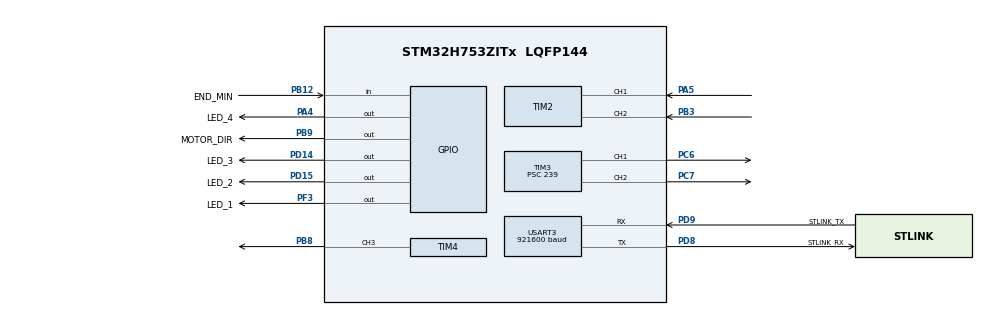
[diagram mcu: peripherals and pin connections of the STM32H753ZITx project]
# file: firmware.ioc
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CORTEX_M7.CPU_DCache=Disabled
CORTEX_M7.CPU_ICache=Disabled
CORTEX_M7.MPU_Control=MPU_PRIVILEGED_DEFAULT
CORTEX_M7.default_mode_Activation=1
Mcu.Family=STM32H7
Mcu.Name=STM32H753ZITx
Mcu.Package=LQFP144
NVIC.PriorityGroup=NVIC_PRIORITYGROUP_4
NVIC.USART3_IRQn=true\:0\:0\:false\:false\:true\:true\:true\:true
PA5.Signal=S_TIM2_CH1_ETR
PB3\ (JTDO/TRACESWO).Signal=S_TIM2_CH2
PC14-OSC32_IN\ (OSC32_IN).Signal=RCC_OSC32_IN
PC15-OSC32_OUT\ (OSC32_OUT).Signal=RCC_OSC32_OUT
PC6.Signal=S_TIM3_CH1
PC7.Signal=S_TIM3_CH2
PD14.GPIO_Label=LED_3
PD14.Signal=GPIO_Output
PD15.GPIO_Label=LED_2
PD15.Signal=GPIO_Output
PD8.GPIO_Label=STLINK_RX
PD8.Mode=Asynchronous
PD8.Signal=USART3_TX
PD9.GPIO_Label=STLINK_TX
PD9.Mode=Asynchronous
PD9.Signal=USART3_RX
PA4.GPIO_Label=LED_4
PA4.Signal=GPIO_Output
PB8.Signal=S_TIM4_CH3
PF3.GPIO_Label=LED_1
PF3.Signal=GPIO_Output
PB9.GPIO_Label=MOTOR_DIR
PB9.Signal=GPIO_Output
PB12.GPIO_Label=END_MIN
PB12.Signal=GPIO_Input
PH0-OSC_IN\ (PH0).Signal=RCC_OSC_IN
PH1-OSC_OUT\ (PH1).Signal=RCC_OSC_OUT
ProjectManager.HeapSize=0x200
ProjectManager.StackSize=0x400
ProjectManager.TargetToolchain=CMake
RCC.ADCFreq_Value=129000000
RCC.APB1Freq_Value=120000000
RCC.APB2Freq_Value=120000000
RCC.APB3Freq_Value=120000000
RCC.APB4Freq_Value=120000000
RCC.CortexFreq_Value=480000000
RCC.D1PPRE=RCC_APB3_DIV2
RCC.D2PPRE1=RCC_APB1_DIV2
RCC.D2PPRE2=RCC_APB2_DIV2
RCC.D3PPRE=RCC_APB4_DIV2
RCC.DIVM1=4
RCC.DIVN1=60
RCC.DIVQ1=4
RCC.HCLKFreq_Value=240000000
RCC.HPRE=RCC_HCLK_DIV2
RCC.HSE_VALUE=8000000
RCC.PLL2FRACN=0
RCC.PLL3FRACN=0
RCC.PLLFRACN=0
RCC.PWR_Regulator_Voltage_Scale=PWR_REGULATOR_VOLTAGE_SCALE0
RCC.SYSCLKFreq_VALUE=480000000
RCC.SYSCLKSource=RCC_SYSCLKSOURCE_PLLCLK
RCC.USBFreq_Value=240000000
SH.S_TIM2_CH1_ETR.0=TIM2_CH1,Encoder_Interface
SH.S_TIM2_CH2.0=TIM2_CH2,Encoder_Interface
SH.S_TIM3_CH1.0=TIM3_CH1,PWM Generation1 CH1
SH.S_TIM3_CH2.0=TIM3_CH2,PWM Generation2 CH2
SH.S_TIM4_CH3.0=TIM4_CH3,PWM Generation3 CH3
TIM2.EncoderMode=TIM_ENCODERMODE_TI12
TIM2.IC1Filter=6
TIM2.IC2Filter=6
TIM3.Channel-PWM\ Generation1\ CH1=TIM_CHANNEL_1
TIM3.Channel-PWM\ Generation2\ CH2=TIM_CHANNEL_2
TIM3.Period=19999
TIM3.Prescaler=239
TIM4.Channel-PWM\ Generation3\ CH3=TIM_CHANNEL_3
TIM4.Period=11999
USART3.BaudRate=921600
USART3.VirtualMode-Asynchronous=VM_ASYNC
VP_MEMORYMAP_VS_MEMORYMAP.Mode=CurAppReg
board=NUCLEO-H753ZI

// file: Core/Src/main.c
/* USER CODE BEGIN Header */
/**
  ******************************************************************************
  * @file           : main.c
  * @brief          : Main program body
  ******************************************************************************
  * @attention
  *
  * Copyright (c) 2026 STMicroelectronics.
  * All rights reserved.
  *
  * This software is licensed under terms that can be found in the LICENSE file
  * in the root directory of this software component.
  * If no LICENSE file comes with this software, it is provided AS-IS.
  *
  ******************************************************************************
  */
/* USER CODE END Header */
#include "main.h"

/* USER CODE BEGIN Includes */
#include "app.h"
#include "bsp/bsp_stm32h7.h"
/* USER CODE END Includes */

TIM_HandleTypeDef htim2;
TIM_HandleTypeDef htim3;
TIM_HandleTypeDef htim4;

UART_HandleTypeDef huart3;

void SystemClock_Config(void);
static void MPU_Config(void);
static void MX_GPIO_Init(void);
static void MX_TIM2_Init(void);
static void MX_TIM3_Init(void);
static void MX_TIM4_Init(void);
static void MX_USART3_UART_Init(void);

int main(void)
{

  /* MPU Configuration--------------------------------------------------------*/
  MPU_Config();

  /* MCU Configuration--------------------------------------------------------*/

  /* Reset of all peripherals, Initializes the Flash interface and the Systick. */
  HAL_Init();

  /* Configure the system clock */
  SystemClock_Config();

  /* Initialize all configured peripherals */
  MX_GPIO_Init();
  MX_TIM2_Init();
  MX_TIM3_Init();
  MX_TIM4_Init();
  MX_USART3_UART_Init();
  /* USER CODE BEGIN 2 */
  bsp_start();
  app_init();
  /* USER CODE END 2 */

  /* Infinite loop */
  while (1)
  {

    /* USER CODE BEGIN 3 */
    app_poll();
  }
  /* USER CODE END 3 */
}

void SystemClock_Config(void)
{
  RCC_OscInitTypeDef RCC_OscInitStruct = {0};
  RCC_ClkInitTypeDef RCC_ClkInitStruct = {0};

  /** Supply configuration update enable
  */
  HAL_PWREx_ConfigSupply(PWR_LDO_SUPPLY);

  /** Configure the main internal regulator output voltage
  */
  __HAL_PWR_VOLTAGESCALING_CONFIG(PWR_REGULATOR_VOLTAGE_SCALE0);

  while(!__HAL_PWR_GET_FLAG(PWR_FLAG_VOSRDY)) {}

  /** Initializes the RCC Oscillators according to the specified parameters
  * in the RCC_OscInitTypeDef structure.
  */
  RCC_OscInitStruct.OscillatorType = RCC_OSCILLATORTYPE_HSI;
  RCC_OscInitStruct.HSIState = RCC_HSI_DIV1;
  RCC_OscInitStruct.HSICalibrationValue = RCC_HSICALIBRATION_DEFAULT;
  RCC_OscInitStruct.PLL.PLLState = RCC_PLL_ON;
  RCC_OscInitStruct.PLL.PLLSource = RCC_PLLSOURCE_HSI;
  RCC_OscInitStruct.PLL.PLLM = 4;
  RCC_OscInitStruct.PLL.PLLN = 60;
  RCC_OscInitStruct.PLL.PLLP = 2;
  RCC_OscInitStruct.PLL.PLLQ = 4;
  RCC_OscInitStruct.PLL.PLLR = 2;
  RCC_OscInitStruct.PLL.PLLRGE = RCC_PLL1VCIRANGE_3;
  RCC_OscInitStruct.PLL.PLLVCOSEL = RCC_PLL1VCOWIDE;
  RCC_OscInitStruct.PLL.PLLFRACN = 0;
  if (HAL_RCC_OscConfig(&RCC_OscInitStruct) != HAL_OK)
  {
    Error_Handler();
  }

  /** Initializes the CPU, AHB and APB buses clocks
  */
  RCC_ClkInitStruct.ClockType = RCC_CLOCKTYPE_HCLK|RCC_CLOCKTYPE_SYSCLK
                              |RCC_CLOCKTYPE_PCLK1|RCC_CLOCKTYPE_PCLK2
                              |RCC_CLOCKTYPE_D3PCLK1|RCC_CLOCKTYPE_D1PCLK1;
  RCC_ClkInitStruct.SYSCLKSource = RCC_SYSCLKSOURCE_PLLCLK;
  RCC_ClkInitStruct.SYSCLKDivider = RCC_SYSCLK_DIV1;
  RCC_ClkInitStruct.AHBCLKDivider = RCC_HCLK_DIV2;
  RCC_ClkInitStruct.APB3CLKDivider = RCC_APB3_DIV2;
  RCC_ClkInitStruct.APB1CLKDivider = RCC_APB1_DIV2;
  RCC_ClkInitStruct.APB2CLKDivider = RCC_APB2_DIV2;
  RCC_ClkInitStruct.APB4CLKDivider = RCC_APB4_DIV2;

  if (HAL_RCC_ClockConfig(&RCC_ClkInitStruct, FLASH_LATENCY_4) != HAL_OK)
  {
    Error_Handler();
  }
}

static void MX_TIM2_Init(void)
{

  TIM_Encoder_InitTypeDef sConfig = {0};
  TIM_MasterConfigTypeDef sMasterConfig = {0};

  htim2.Instance = TIM2;
  htim2.Init.Prescaler = 0;
  htim2.Init.CounterMode = TIM_COUNTERMODE_UP;
  htim2.Init.Period = 4294967295;
  htim2.Init.ClockDivision = TIM_CLOCKDIVISION_DIV1;
  htim2.Init.AutoReloadPreload = TIM_AUTORELOAD_PRELOAD_DISABLE;
  sConfig.EncoderMode = TIM_ENCODERMODE_TI12;
  sConfig.IC1Polarity = TIM_ICPOLARITY_RISING;
  sConfig.IC1Selection = TIM_ICSELECTION_DIRECTTI;
  sConfig.IC1Prescaler = TIM_ICPSC_DIV1;
  sConfig.IC1Filter = 6;
  sConfig.IC2Polarity = TIM_ICPOLARITY_RISING;
  sConfig.IC2Selection = TIM_ICSELECTION_DIRECTTI;
  sConfig.IC2Prescaler = TIM_ICPSC_DIV1;
  sConfig.IC2Filter = 6;
  if (HAL_TIM_Encoder_Init(&htim2, &sConfig) != HAL_OK)
  {
    Error_Handler();
  }
  sMasterConfig.MasterOutputTrigger = TIM_TRGO_RESET;
  sMasterConfig.MasterSlaveMode = TIM_MASTERSLAVEMODE_DISABLE;
  if (HAL_TIMEx_MasterConfigSynchronization(&htim2, &sMasterConfig) != HAL_OK)
  {
    Error_Handler();
  }

}

static void MX_TIM3_Init(void)
{

  TIM_MasterConfigTypeDef sMasterConfig = {0};
  TIM_OC_InitTypeDef sConfigOC = {0};

  htim3.Instance = TIM3;
  htim3.Init.Prescaler = 239;
  htim3.Init.CounterMode = TIM_COUNTERMODE_UP;
  htim3.Init.Period = 19999;
  htim3.Init.ClockDivision = TIM_CLOCKDIVISION_DIV1;
  htim3.Init.AutoReloadPreload = TIM_AUTORELOAD_PRELOAD_DISABLE;
  if (HAL_TIM_PWM_Init(&htim3) != HAL_OK)
  {
    Error_Handler();
  }
  sMasterConfig.MasterOutputTrigger = TIM_TRGO_RESET;
  sMasterConfig.MasterSlaveMode = TIM_MASTERSLAVEMODE_DISABLE;
  if (HAL_TIMEx_MasterConfigSynchronization(&htim3, &sMasterConfig) != HAL_OK)
  {
    Error_Handler();
  }
  sConfigOC.OCMode = TIM_OCMODE_PWM1;
  sConfigOC.Pulse = 0;
  sConfigOC.OCPolarity = TIM_OCPOLARITY_HIGH;
  sConfigOC.OCFastMode = TIM_OCFAST_DISABLE;
  if (HAL_TIM_PWM_ConfigChannel(&htim3, &sConfigOC, TIM_CHANNEL_1) != HAL_OK)
  {
    Error_Handler();
  }
  if (HAL_TIM_PWM_ConfigChannel(&htim3, &sConfigOC, TIM_CHANNEL_2) != HAL_OK)
  {
    Error_Handler();
  }
  HAL_TIM_MspPostInit(&htim3);

}

static void MX_TIM4_Init(void)
{

  TIM_MasterConfigTypeDef sMasterConfig = {0};
  TIM_OC_InitTypeDef sConfigOC = {0};

  htim4.Instance = TIM4;
  htim4.Init.Prescaler = 0;
  htim4.Init.CounterMode = TIM_COUNTERMODE_UP;
  htim4.Init.Period = 11999;
  htim4.Init.ClockDivision = TIM_CLOCKDIVISION_DIV1;
  htim4.Init.AutoReloadPreload = TIM_AUTORELOAD_PRELOAD_DISABLE;
  if (HAL_TIM_PWM_Init(&htim4) != HAL_OK)
  {
    Error_Handler();
  }
  sMasterConfig.MasterOutputTrigger = TIM_TRGO_RESET;
  sMasterConfig.MasterSlaveMode = TIM_MASTERSLAVEMODE_DISABLE;
  if (HAL_TIMEx_MasterConfigSynchronization(&htim4, &sMasterConfig) != HAL_OK)
  {
    Error_Handler();
  }
  sConfigOC.OCMode = TIM_OCMODE_PWM1;
  sConfigOC.Pulse = 0;
  sConfigOC.OCPolarity = TIM_OCPOLARITY_HIGH;
  sConfigOC.OCFastMode = TIM_OCFAST_DISABLE;
  if (HAL_TIM_PWM_ConfigChannel(&htim4, &sConfigOC, TIM_CHANNEL_3) != HAL_OK)
  {
    Error_Handler();
  }
  HAL_TIM_MspPostInit(&htim4);

}

static void MX_USART3_UART_Init(void)
{

  huart3.Instance = USART3;
  huart3.Init.BaudRate = 921600;
  huart3.Init.WordLength = UART_WORDLENGTH_8B;
  huart3.Init.StopBits = UART_STOPBITS_1;
  huart3.Init.Parity = UART_PARITY_NONE;
  huart3.Init.Mode = UART_MODE_TX_RX;
  huart3.Init.HwFlowCtl = UART_HWCONTROL_NONE;
  huart3.Init.OverSampling = UART_OVERSAMPLING_16;
  huart3.Init.OneBitSampling = UART_ONE_BIT_SAMPLE_DISABLE;
  huart3.Init.ClockPrescaler = UART_PRESCALER_DIV1;
  huart3.AdvancedInit.AdvFeatureInit = UART_ADVFEATURE_NO_INIT;
  if (HAL_UART_Init(&huart3) != HAL_OK)
  {
    Error_Handler();
  }
  if (HAL_UARTEx_SetTxFifoThreshold(&huart3, UART_TXFIFO_THRESHOLD_1_8) != HAL_OK)
  {
    Error_Handler();
  }
  if (HAL_UARTEx_SetRxFifoThreshold(&huart3, UART_RXFIFO_THRESHOLD_1_8) != HAL_OK)
  {
    Error_Handler();
  }
  if (HAL_UARTEx_DisableFifoMode(&huart3) != HAL_OK)
  {
    Error_Handler();
  }

}

static void MX_GPIO_Init(void)
{
  GPIO_InitTypeDef GPIO_InitStruct = {0};

  /* GPIO Ports Clock Enable */
  __HAL_RCC_GPIOC_CLK_ENABLE();
  __HAL_RCC_GPIOH_CLK_ENABLE();
  __HAL_RCC_GPIOA_CLK_ENABLE();
  __HAL_RCC_GPIOF_CLK_ENABLE();
  __HAL_RCC_GPIOE_CLK_ENABLE();
  __HAL_RCC_GPIOD_CLK_ENABLE();
  __HAL_RCC_GPIOB_CLK_ENABLE();

  /*Configure GPIO pin Output Level */
  HAL_GPIO_WritePin(LED_1_GPIO_Port, LED_1_Pin, GPIO_PIN_RESET);

  /*Configure GPIO pin Output Level */
  HAL_GPIO_WritePin(LED_4_GPIO_Port, LED_4_Pin, GPIO_PIN_RESET);

  /*Configure GPIO pin Output Level */
  HAL_GPIO_WritePin(GPIOD, LED_3_Pin|LED_2_Pin, GPIO_PIN_RESET);

  /*Configure GPIO pin Output Level */
  HAL_GPIO_WritePin(MOTOR_DIR_GPIO_Port, MOTOR_DIR_Pin, GPIO_PIN_RESET);

  /*Configure GPIO pin : LED_1_Pin */
  GPIO_InitStruct.Pin = LED_1_Pin;
  GPIO_InitStruct.Mode = GPIO_MODE_OUTPUT_PP;
  GPIO_InitStruct.Pull = GPIO_NOPULL;
  GPIO_InitStruct.Speed = GPIO_SPEED_FREQ_LOW;
  HAL_GPIO_Init(LED_1_GPIO_Port, &GPIO_InitStruct);

  /*Configure GPIO pin : LED_4_Pin */
  GPIO_InitStruct.Pin = LED_4_Pin;
  GPIO_InitStruct.Mode = GPIO_MODE_OUTPUT_PP;
  GPIO_InitStruct.Pull = GPIO_NOPULL;
  GPIO_InitStruct.Speed = GPIO_SPEED_FREQ_LOW;
  HAL_GPIO_Init(LED_4_GPIO_Port, &GPIO_InitStruct);

  /*Configure GPIO pin : END_MIN_Pin */
  GPIO_InitStruct.Pin = END_MIN_Pin;
  GPIO_InitStruct.Mode = GPIO_MODE_INPUT;
  GPIO_InitStruct.Pull = GPIO_NOPULL;
  HAL_GPIO_Init(END_MIN_GPIO_Port, &GPIO_InitStruct);

  /*Configure GPIO pins : LED_3_Pin LED_2_Pin */
  GPIO_InitStruct.Pin = LED_3_Pin|LED_2_Pin;
  GPIO_InitStruct.Mode = GPIO_MODE_OUTPUT_PP;
  GPIO_InitStruct.Pull = GPIO_NOPULL;
  GPIO_InitStruct.Speed = GPIO_SPEED_FREQ_LOW;
  HAL_GPIO_Init(GPIOD, &GPIO_InitStruct);

  /*Configure GPIO pin : MOTOR_DIR_Pin */
  GPIO_InitStruct.Pin = MOTOR_DIR_Pin;
  GPIO_InitStruct.Mode = GPIO_MODE_OUTPUT_PP;
  GPIO_InitStruct.Pull = GPIO_NOPULL;
  GPIO_InitStruct.Speed = GPIO_SPEED_FREQ_LOW;
  HAL_GPIO_Init(MOTOR_DIR_GPIO_Port, &GPIO_InitStruct);

}

 /* MPU Configuration */

void MPU_Config(void)
{
  MPU_Region_InitTypeDef MPU_InitStruct = {0};

  /* Disables the MPU */
  HAL_MPU_Disable();

  /** Initializes and configures the Region and the memory to be protected
  */
  MPU_InitStruct.Enable = MPU_REGION_ENABLE;
  MPU_InitStruct.Number = MPU_REGION_NUMBER0;
  MPU_InitStruct.BaseAddress = 0x0;
  MPU_InitStruct.Size = MPU_REGION_SIZE_4GB;
  MPU_InitStruct.SubRegionDisable = 0x87;
  MPU_InitStruct.TypeExtField = MPU_TEX_LEVEL0;
  MPU_InitStruct.AccessPermission = MPU_REGION_NO_ACCESS;
  MPU_InitStruct.DisableExec = MPU_INSTRUCTION_ACCESS_DISABLE;
  MPU_InitStruct.IsShareable = MPU_ACCESS_SHAREABLE;
  MPU_InitStruct.IsCacheable = MPU_ACCESS_NOT_CACHEABLE;
  MPU_InitStruct.IsBufferable = MPU_ACCESS_NOT_BUFFERABLE;

  HAL_MPU_ConfigRegion(&MPU_InitStruct);
  /* Enables the MPU */
  HAL_MPU_Enable(MPU_PRIVILEGED_DEFAULT);

}

void Error_Handler(void)
{
  __disable_irq();
  while (1)
  {
  }
}
